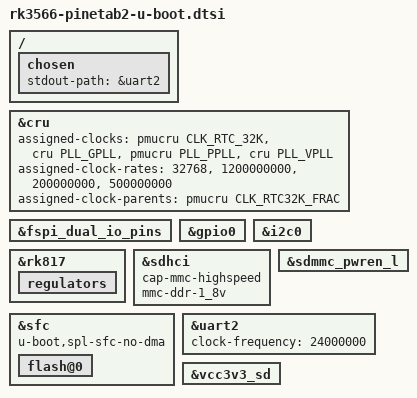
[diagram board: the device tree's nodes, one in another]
// SPDX-License-Identifier: GPL-2.0+

#include "rk356x-u-boot.dtsi"

/ {
	chosen {
		stdout-path = &uart2;
	};
};

&cru {
	assigned-clocks = <&pmucru CLK_RTC_32K>, <&cru PLL_GPLL>, <&pmucru PLL_PPLL>, <&cru PLL_VPLL>;
	assigned-clock-rates = <32768>, <1200000000>, <200000000>, <500000000>;
	assigned-clock-parents = <&pmucru CLK_RTC32K_FRAC>;
};

&fspi_dual_io_pins {
	bootph-all;
};

&gpio0 {
	bootph-all;
};

&i2c0 {
	bootph-pre-ram;
};

&rk817 {
	bootph-pre-ram;

	regulators {
		bootph-pre-ram;
	};
};

&sdhci {
	cap-mmc-highspeed;
	mmc-ddr-1_8v;
};

&sdmmc_pwren_l {
	bootph-all;
};

&sfc {
	bootph-pre-ram;
	u-boot,spl-sfc-no-dma;

	flash@0 {
		bootph-pre-ram;
	};
};

&uart2 {
	bootph-all;
	clock-frequency = <24000000>;
	status = "okay";
};

&vcc3v3_sd {
	bootph-pre-ram;
};
